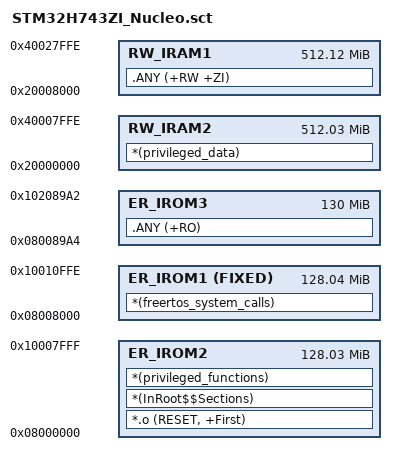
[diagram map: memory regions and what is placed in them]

; *************************************************************
; *** Scatter-Loading Description File generated by uVision ***
; *************************************************************

LR_IROM1 0x08000000 0x00200000    {    ; load region size_region
  ER_IROM2 0x08000000 0x08008000  {  
   *.o (RESET, +First)
   *(InRoot$$Sections) ; load address = execution address
   *(privileged_functions)
  }
  ER_IROM1 0x08008000 FIXED  0x08008FFF{  ; load address = execution address
   *(freertos_system_calls)
  }
  
  ER_IROM3 0x080089a4  0x081FFFFF  {; load address = execution address
   .ANY (+RO)
  }
  
  RW_IRAM2 0x20000000 0x20007FFF  {  ; RW data
   *(privileged_data)
       }
  RW_IRAM1 0x20008000 0x2001FFFF  {  ; RW data
   .ANY (+RW +ZI)
  }
}
